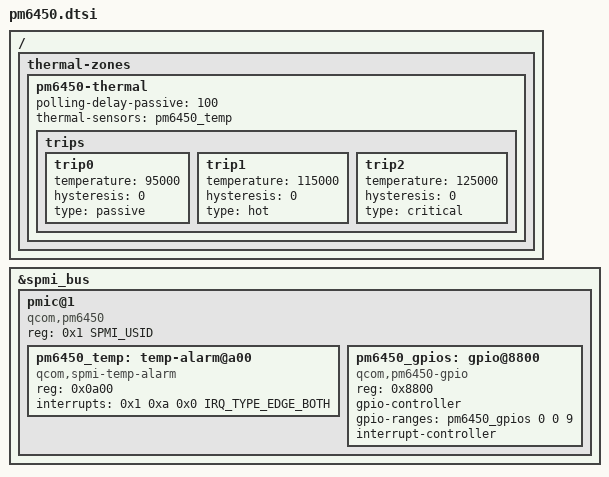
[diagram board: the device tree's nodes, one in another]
// SPDX-License-Identifier: BSD-3-Clause
/*
 * Copyright (c) 2025 Artur Weber <aweber.kernel@gmail.com>
 */

#include <dt-bindings/spmi/spmi.h>

/ {
	thermal-zones {
		pm6450-thermal {
			polling-delay-passive = <100>;

			thermal-sensors = <&pm6450_temp>;

			trips {
				trip0 {
					temperature = <95000>;
					hysteresis = <0>;
					type = "passive";
				};

				trip1 {
					temperature = <115000>;
					hysteresis = <0>;
					type = "hot";
				};

				trip2 {
					temperature = <125000>;
					hysteresis = <0>;
					type = "critical";
				};
			};
		};
	};
};

&spmi_bus {
	pmic@1 {
		compatible = "qcom,pm6450", "qcom,spmi-pmic";
		reg = <0x1 SPMI_USID>;

		pm6450_temp: temp-alarm@a00 {
			compatible = "qcom,spmi-temp-alarm";
			reg = <0x0a00>;
			interrupts = <0x1 0xa 0x0 IRQ_TYPE_EDGE_BOTH>;
			//io-channels = <&pm7250b_adc ADC5_DIE_TEMP>;
			//io-channel-names = "thermal";
			#thermal-sensor-cells = <0>;
		};

		pm6450_gpios: gpio@8800 {
			compatible = "qcom,pm6450-gpio", "qcom,spmi-gpio";
			reg = <0x8800>;
			gpio-controller;
			gpio-ranges = <&pm6450_gpios 0 0 9>;
			#gpio-cells = <2>;
			interrupt-controller;
			#interrupt-cells = <2>;
		};

		// TODO: PWM/LPG @ 0xe800
	};
};
